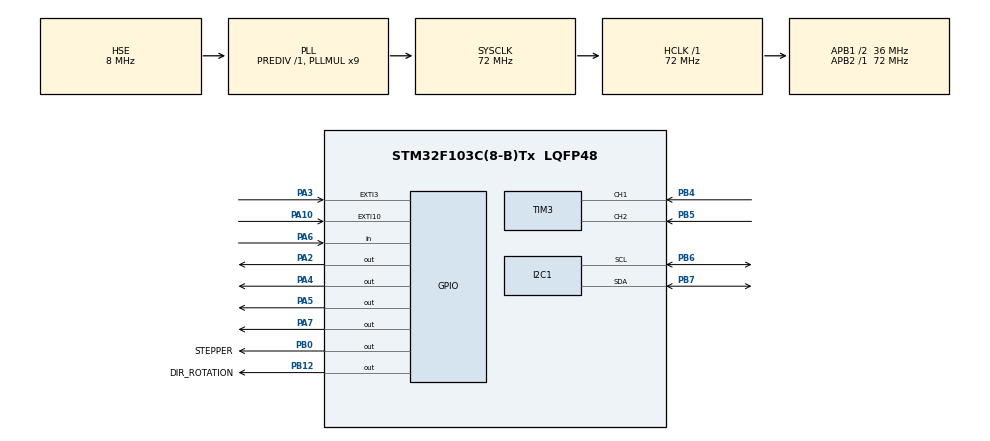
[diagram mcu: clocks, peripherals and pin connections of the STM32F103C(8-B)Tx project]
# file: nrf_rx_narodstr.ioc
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Mcu.Family=STM32F1
Mcu.Name=STM32F103C(8-B)Tx
Mcu.Package=LQFP48
NVIC.EXTI15_10_IRQn=true\:1\:0\:true\:false\:true\:true\:true\:true
NVIC.EXTI3_IRQn=true\:2\:0\:true\:false\:true\:true\:true\:true
NVIC.PriorityGroup=NVIC_PRIORITYGROUP_4
NVIC.TIM1_UP_IRQn=true\:0\:0\:false\:false\:true\:true\:true\:true
NVIC.TIM3_IRQn=true\:4\:0\:true\:false\:true\:true\:true\:true
PA10.GPIO_ModeDefaultEXTI=GPIO_MODE_IT_FALLING
PA10.Signal=GPXTI10
PA13.Mode=Serial_Wire
PA13.Signal=SYS_JTMS-SWDIO
PA14.Mode=Serial_Wire
PA14.Signal=SYS_JTCK-SWCLK
PA2.GPIO_Speed=GPIO_SPEED_FREQ_HIGH
PA2.Signal=GPIO_Output
PA3.GPIO_ModeDefaultEXTI=GPIO_MODE_IT_FALLING
PA3.Signal=GPXTI3
PA4.GPIO_Speed=GPIO_SPEED_FREQ_HIGH
PA4.PinState=GPIO_PIN_SET
PA4.Signal=GPIO_Output
PA5.GPIO_Speed=GPIO_SPEED_FREQ_HIGH
PA5.Signal=GPIO_Output
PA6.Signal=GPIO_Input
PA7.GPIO_Speed=GPIO_SPEED_FREQ_HIGH
PA7.Signal=GPIO_Output
PB0.GPIO_Label=STEPPER
PB0.GPIO_Speed=GPIO_SPEED_FREQ_HIGH
PB0.Signal=GPIO_Output
PB12.GPIO_Label=DIR_ROTATION
PB12.GPIO_Speed=GPIO_SPEED_FREQ_HIGH
PB12.PinState=GPIO_PIN_SET
PB12.Signal=GPIO_Output
PB4.GPIO_PuPd=GPIO_PULLUP
PB4.Signal=S_TIM3_CH1
PB5.GPIO_PuPd=GPIO_PULLUP
PB5.Signal=S_TIM3_CH2
PB6.Mode=I2C
PB6.Signal=I2C1_SCL
PB7.Mode=I2C
PB7.Signal=I2C1_SDA
PD0-OSC_IN.Mode=HSE-External-Oscillator
PD0-OSC_IN.Signal=RCC_OSC_IN
PD1-OSC_OUT.Mode=HSE-External-Oscillator
PD1-OSC_OUT.Signal=RCC_OSC_OUT
ProjectManager.HeapSize=0x200
ProjectManager.StackSize=0x400
ProjectManager.TargetToolchain=CMake
RCC.AHBFreq_Value=72000000
RCC.APB1CLKDivider=RCC_HCLK_DIV2
RCC.APB1Freq_Value=36000000
RCC.APB1TimFreq_Value=72000000
RCC.APB2Freq_Value=72000000
RCC.APB2TimFreq_Value=72000000
RCC.HCLKFreq_Value=72000000
RCC.PLLMUL=RCC_PLL_MUL9
RCC.PLLSourceVirtual=RCC_PLLSOURCE_HSE
RCC.SYSCLKFreq_VALUE=72000000
RCC.SYSCLKSource=RCC_SYSCLKSOURCE_PLLCLK
RCC.USBFreq_Value=72000000
SH.S_TIM3_CH1.0=TIM3_CH1,Encoder_Interface
SH.S_TIM3_CH2.0=TIM3_CH2,Encoder_Interface
TIM1.Prescaler=9
TIM2.Prescaler=71
TIM3.AutoReloadPreload=TIM_AUTORELOAD_PRELOAD_ENABLE
TIM3.EncoderMode=TIM_ENCODERMODE_TI12
TIM3.IC1Filter=10
TIM3.IC1Polarity=TIM_ICPOLARITY_FALLING
TIM3.IC2Filter=10
TIM3.IC2Polarity=TIM_ICPOLARITY_FALLING
TIM4.Prescaler=71
VP_TIM1_VS_ClockSourceINT.Mode=Internal
VP_TIM2_VS_ClockSourceINT.Mode=Internal
VP_TIM4_VS_ClockSourceINT.Mode=Internal
board=custom

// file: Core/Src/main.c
/* USER CODE BEGIN Header */
/**
  ******************************************************************************
  * @file           : main.c
  * @brief          : Main program body
  ******************************************************************************
  * @attention
  *
  * Copyright (c) 2024 STMicroelectronics.
  * All rights reserved.
  *
  * This software is licensed under terms that can be found in the LICENSE file
  * in the root directory of this software component.
  * If no LICENSE file comes with this software, it is provided AS-IS.
  *
  ******************************************************************************
  */
/* USER CODE END Header */
#include "main.h"

/* USER CODE BEGIN Includes */
#include "app_lev_stend.h"
/* USER CODE END Includes */

I2C_HandleTypeDef hi2c1;

TIM_HandleTypeDef htim1;
TIM_HandleTypeDef htim2;
TIM_HandleTypeDef htim3;
TIM_HandleTypeDef htim4;

void SystemClock_Config(void);
static void MX_GPIO_Init(void);
static void MX_TIM2_Init(void);
static void MX_I2C1_Init(void);
static void MX_TIM1_Init(void);
static void MX_TIM3_Init(void);
static void MX_TIM4_Init(void);

int main(void)
{

  /* MCU Configuration--------------------------------------------------------*/

  /* Reset of all peripherals, Initializes the Flash interface and the Systick. */
  HAL_Init();

  /* Configure the system clock */
  SystemClock_Config();

  /* Initialize all configured peripherals */
  MX_GPIO_Init();
  MX_TIM2_Init();
  MX_I2C1_Init();
  MX_TIM1_Init();
  MX_TIM3_Init();
  MX_TIM4_Init();
  /* USER CODE BEGIN 2 */
  init_stend();
  /* USER CODE END 2 */

  /* Infinite loop */
  /* USER CODE BEGIN WHILE */
  while (1)
  {

	MotorSmoothStart();
    /* USER CODE END WHILE */

  }
}

void SystemClock_Config(void)
{
  RCC_OscInitTypeDef RCC_OscInitStruct = {0};
  RCC_ClkInitTypeDef RCC_ClkInitStruct = {0};

  /** Initializes the RCC Oscillators according to the specified parameters
  * in the RCC_OscInitTypeDef structure.
  */
  RCC_OscInitStruct.OscillatorType = RCC_OSCILLATORTYPE_HSE;
  RCC_OscInitStruct.HSEState = RCC_HSE_ON;
  RCC_OscInitStruct.HSEPredivValue = RCC_HSE_PREDIV_DIV1;
  RCC_OscInitStruct.HSIState = RCC_HSI_ON;
  RCC_OscInitStruct.PLL.PLLState = RCC_PLL_ON;
  RCC_OscInitStruct.PLL.PLLSource = RCC_PLLSOURCE_HSE;
  RCC_OscInitStruct.PLL.PLLMUL = RCC_PLL_MUL9;
  if (HAL_RCC_OscConfig(&RCC_OscInitStruct) != HAL_OK)
  {
    Error_Handler();
  }

  /** Initializes the CPU, AHB and APB buses clocks
  */
  RCC_ClkInitStruct.ClockType = RCC_CLOCKTYPE_HCLK|RCC_CLOCKTYPE_SYSCLK
                              |RCC_CLOCKTYPE_PCLK1|RCC_CLOCKTYPE_PCLK2;
  RCC_ClkInitStruct.SYSCLKSource = RCC_SYSCLKSOURCE_PLLCLK;
  RCC_ClkInitStruct.AHBCLKDivider = RCC_SYSCLK_DIV1;
  RCC_ClkInitStruct.APB1CLKDivider = RCC_HCLK_DIV2;
  RCC_ClkInitStruct.APB2CLKDivider = RCC_HCLK_DIV1;

  if (HAL_RCC_ClockConfig(&RCC_ClkInitStruct, FLASH_LATENCY_2) != HAL_OK)
  {
    Error_Handler();
  }
}

static void MX_I2C1_Init(void)
{

  hi2c1.Instance = I2C1;
  hi2c1.Init.ClockSpeed = 100000;
  hi2c1.Init.DutyCycle = I2C_DUTYCYCLE_2;
  hi2c1.Init.OwnAddress1 = 0;
  hi2c1.Init.AddressingMode = I2C_ADDRESSINGMODE_7BIT;
  hi2c1.Init.DualAddressMode = I2C_DUALADDRESS_DISABLE;
  hi2c1.Init.OwnAddress2 = 0;
  hi2c1.Init.GeneralCallMode = I2C_GENERALCALL_DISABLE;
  hi2c1.Init.NoStretchMode = I2C_NOSTRETCH_DISABLE;
  if (HAL_I2C_Init(&hi2c1) != HAL_OK)
  {
    Error_Handler();
  }

}

static void MX_TIM1_Init(void)
{

  TIM_ClockConfigTypeDef sClockSourceConfig = {0};
  TIM_MasterConfigTypeDef sMasterConfig = {0};

  htim1.Instance = TIM1;
  htim1.Init.Prescaler = 9;
  htim1.Init.CounterMode = TIM_COUNTERMODE_UP;
  htim1.Init.Period = 65535;
  htim1.Init.ClockDivision = TIM_CLOCKDIVISION_DIV1;
  htim1.Init.RepetitionCounter = 0;
  htim1.Init.AutoReloadPreload = TIM_AUTORELOAD_PRELOAD_DISABLE;
  if (HAL_TIM_Base_Init(&htim1) != HAL_OK)
  {
    Error_Handler();
  }
  sClockSourceConfig.ClockSource = TIM_CLOCKSOURCE_INTERNAL;
  if (HAL_TIM_ConfigClockSource(&htim1, &sClockSourceConfig) != HAL_OK)
  {
    Error_Handler();
  }
  sMasterConfig.MasterOutputTrigger = TIM_TRGO_RESET;
  sMasterConfig.MasterSlaveMode = TIM_MASTERSLAVEMODE_DISABLE;
  if (HAL_TIMEx_MasterConfigSynchronization(&htim1, &sMasterConfig) != HAL_OK)
  {
    Error_Handler();
  }

}

static void MX_TIM2_Init(void)
{

  TIM_ClockConfigTypeDef sClockSourceConfig = {0};
  TIM_MasterConfigTypeDef sMasterConfig = {0};

  htim2.Instance = TIM2;
  htim2.Init.Prescaler = 71;
  htim2.Init.CounterMode = TIM_COUNTERMODE_UP;
  htim2.Init.Period = 65535;
  htim2.Init.ClockDivision = TIM_CLOCKDIVISION_DIV1;
  htim2.Init.AutoReloadPreload = TIM_AUTORELOAD_PRELOAD_DISABLE;
  if (HAL_TIM_Base_Init(&htim2) != HAL_OK)
  {
    Error_Handler();
  }
  sClockSourceConfig.ClockSource = TIM_CLOCKSOURCE_INTERNAL;
  if (HAL_TIM_ConfigClockSource(&htim2, &sClockSourceConfig) != HAL_OK)
  {
    Error_Handler();
  }
  sMasterConfig.MasterOutputTrigger = TIM_TRGO_RESET;
  sMasterConfig.MasterSlaveMode = TIM_MASTERSLAVEMODE_DISABLE;
  if (HAL_TIMEx_MasterConfigSynchronization(&htim2, &sMasterConfig) != HAL_OK)
  {
    Error_Handler();
  }

}

static void MX_TIM3_Init(void)
{

  TIM_Encoder_InitTypeDef sConfig = {0};
  TIM_MasterConfigTypeDef sMasterConfig = {0};

  htim3.Instance = TIM3;
  htim3.Init.Prescaler = 0;
  htim3.Init.CounterMode = TIM_COUNTERMODE_UP;
  htim3.Init.Period = 65535;
  htim3.Init.ClockDivision = TIM_CLOCKDIVISION_DIV1;
  htim3.Init.AutoReloadPreload = TIM_AUTORELOAD_PRELOAD_ENABLE;
  sConfig.EncoderMode = TIM_ENCODERMODE_TI12;
  sConfig.IC1Polarity = TIM_ICPOLARITY_FALLING;
  sConfig.IC1Selection = TIM_ICSELECTION_DIRECTTI;
  sConfig.IC1Prescaler = TIM_ICPSC_DIV1;
  sConfig.IC1Filter = 10;
  sConfig.IC2Polarity = TIM_ICPOLARITY_FALLING;
  sConfig.IC2Selection = TIM_ICSELECTION_DIRECTTI;
  sConfig.IC2Prescaler = TIM_ICPSC_DIV1;
  sConfig.IC2Filter = 10;
  if (HAL_TIM_Encoder_Init(&htim3, &sConfig) != HAL_OK)
  {
    Error_Handler();
  }
  sMasterConfig.MasterOutputTrigger = TIM_TRGO_RESET;
  sMasterConfig.MasterSlaveMode = TIM_MASTERSLAVEMODE_DISABLE;
  if (HAL_TIMEx_MasterConfigSynchronization(&htim3, &sMasterConfig) != HAL_OK)
  {
    Error_Handler();
  }

}

static void MX_TIM4_Init(void)
{

  TIM_ClockConfigTypeDef sClockSourceConfig = {0};
  TIM_MasterConfigTypeDef sMasterConfig = {0};

  htim4.Instance = TIM4;
  htim4.Init.Prescaler = 71;
  htim4.Init.CounterMode = TIM_COUNTERMODE_UP;
  htim4.Init.Period = 65535;
  htim4.Init.ClockDivision = TIM_CLOCKDIVISION_DIV1;
  htim4.Init.AutoReloadPreload = TIM_AUTORELOAD_PRELOAD_DISABLE;
  if (HAL_TIM_Base_Init(&htim4) != HAL_OK)
  {
    Error_Handler();
  }
  sClockSourceConfig.ClockSource = TIM_CLOCKSOURCE_INTERNAL;
  if (HAL_TIM_ConfigClockSource(&htim4, &sClockSourceConfig) != HAL_OK)
  {
    Error_Handler();
  }
  sMasterConfig.MasterOutputTrigger = TIM_TRGO_RESET;
  sMasterConfig.MasterSlaveMode = TIM_MASTERSLAVEMODE_DISABLE;
  if (HAL_TIMEx_MasterConfigSynchronization(&htim4, &sMasterConfig) != HAL_OK)
  {
    Error_Handler();
  }

}

static void MX_GPIO_Init(void)
{
  GPIO_InitTypeDef GPIO_InitStruct = {0};

  /* GPIO Ports Clock Enable */
  __HAL_RCC_GPIOC_CLK_ENABLE();
  __HAL_RCC_GPIOD_CLK_ENABLE();
  __HAL_RCC_GPIOA_CLK_ENABLE();
  __HAL_RCC_GPIOB_CLK_ENABLE();

  /*Configure GPIO pin Output Level */
  HAL_GPIO_WritePin(GPIOA, GPIO_PIN_2|GPIO_PIN_5|GPIO_PIN_7, GPIO_PIN_RESET);

  /*Configure GPIO pin Output Level */
  HAL_GPIO_WritePin(GPIOA, GPIO_PIN_4, GPIO_PIN_SET);

  /*Configure GPIO pin Output Level */
  HAL_GPIO_WritePin(STEPPER_GPIO_Port, STEPPER_Pin, GPIO_PIN_RESET);

  /*Configure GPIO pin Output Level */
  HAL_GPIO_WritePin(DIR_ROTATION_GPIO_Port, DIR_ROTATION_Pin, GPIO_PIN_SET);

  /*Configure GPIO pins : PC13 PC14 PC15 */
  GPIO_InitStruct.Pin = GPIO_PIN_13|GPIO_PIN_14|GPIO_PIN_15;
  GPIO_InitStruct.Mode = GPIO_MODE_ANALOG;
  HAL_GPIO_Init(GPIOC, &GPIO_InitStruct);

  /*Configure GPIO pins : PA0 PA1 PA8 PA9
                           PA11 PA12 PA15 */
  GPIO_InitStruct.Pin = GPIO_PIN_0|GPIO_PIN_1|GPIO_PIN_8|GPIO_PIN_9
                          |GPIO_PIN_11|GPIO_PIN_12|GPIO_PIN_15;
  GPIO_InitStruct.Mode = GPIO_MODE_ANALOG;
  HAL_GPIO_Init(GPIOA, &GPIO_InitStruct);

  /*Configure GPIO pins : PA2 PA4 PA5 PA7 */
  GPIO_InitStruct.Pin = GPIO_PIN_2|GPIO_PIN_4|GPIO_PIN_5|GPIO_PIN_7;
  GPIO_InitStruct.Mode = GPIO_MODE_OUTPUT_PP;
  GPIO_InitStruct.Pull = GPIO_NOPULL;
  GPIO_InitStruct.Speed = GPIO_SPEED_FREQ_HIGH;
  HAL_GPIO_Init(GPIOA, &GPIO_InitStruct);

  /*Configure GPIO pins : PA3 PA10 */
  GPIO_InitStruct.Pin = GPIO_PIN_3|GPIO_PIN_10;
  GPIO_InitStruct.Mode = GPIO_MODE_IT_FALLING;
  GPIO_InitStruct.Pull = GPIO_NOPULL;
  HAL_GPIO_Init(GPIOA, &GPIO_InitStruct);

  /*Configure GPIO pin : PA6 */
  GPIO_InitStruct.Pin = GPIO_PIN_6;
  GPIO_InitStruct.Mode = GPIO_MODE_INPUT;
  GPIO_InitStruct.Pull = GPIO_NOPULL;
  HAL_GPIO_Init(GPIOA, &GPIO_InitStruct);

  /*Configure GPIO pins : STEPPER_Pin DIR_ROTATION_Pin */
  GPIO_InitStruct.Pin = STEPPER_Pin|DIR_ROTATION_Pin;
  GPIO_InitStruct.Mode = GPIO_MODE_OUTPUT_PP;
  GPIO_InitStruct.Pull = GPIO_NOPULL;
  GPIO_InitStruct.Speed = GPIO_SPEED_FREQ_HIGH;
  HAL_GPIO_Init(GPIOB, &GPIO_InitStruct);

  /*Configure GPIO pins : PB1 PB2 PB10 PB11
                           PB13 PB14 PB15 PB3
                           PB8 PB9 */
  GPIO_InitStruct.Pin = GPIO_PIN_1|GPIO_PIN_2|GPIO_PIN_10|GPIO_PIN_11
                          |GPIO_PIN_13|GPIO_PIN_14|GPIO_PIN_15|GPIO_PIN_3
                          |GPIO_PIN_8|GPIO_PIN_9;
  GPIO_InitStruct.Mode = GPIO_MODE_ANALOG;
  HAL_GPIO_Init(GPIOB, &GPIO_InitStruct);

  /* EXTI interrupt init*/
  HAL_NVIC_SetPriority(EXTI3_IRQn, 2, 0);
  HAL_NVIC_EnableIRQ(EXTI3_IRQn);

  HAL_NVIC_SetPriority(EXTI15_10_IRQn, 1, 0);
  HAL_NVIC_EnableIRQ(EXTI15_10_IRQn);

}

void Error_Handler(void)
{
  __disable_irq();
  while (1)
  {
  }
}
